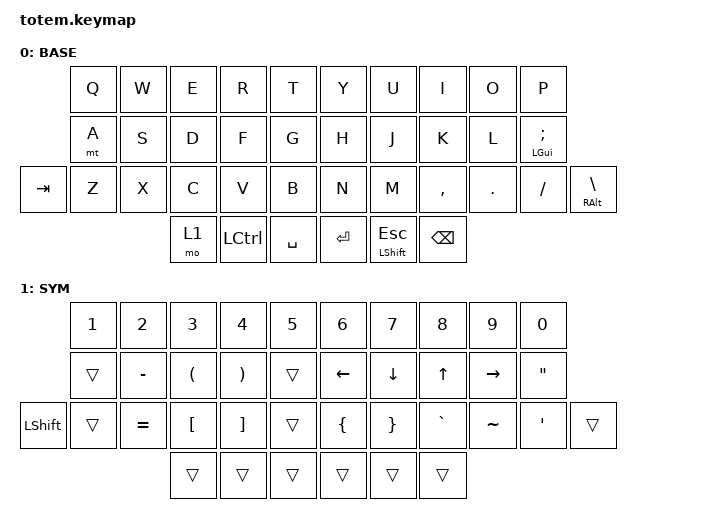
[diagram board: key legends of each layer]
//
//                                                        ▀▀▀▀▀     ▀▀▀▀▀          ▀▀█▀▀
//                                                        ▄▀▀▀▄  ▄  ▄▀▀▀▄  ▄  ▄▀▀▀▄  █  ▄▀▀▀▄
//                                                        █   █  █  █   █  █  █   █  █  █   █
//                                                         ▀▀▀   █   ▀▀▀   █   ▀▀▀   ▀   ▀▀▀
//                                                               █      ▄▄▄█▄▄▄    █   █  
//                                                               ▀      █  █  █     █▄█
//                                                             ▀▀▀▀▀    █  █  █      ▀
//                                                                      ▀  ▀  ▀
//
// ▄▄▄▄▄▄▄▄▄▄▄▄▄▄▄▄▄▄▄▄▄▄▄▄▄▄▄▄▄▄▄▄▄▄▄▄▄▄▄▄▄▄▄▄▄▄▄▄▄▄▄▄▄▄▄▄▄▄▄▄▄▄▄▄▄▄▄▄▄▄▄▄▄▄▄▄▄▄▄▄▄▄▄▄▄▄▄▄▄▄▄▄▄▄▄▄▄▄▄▄▄▄▄▄▄▄▄▄▄▄▄▄▄▄▄▄▄▄▄▄▄▄▄▄▄▄▄▄▄▄▄▄▄▄▄▄▄▄▄▄▄▄▄▄▄▄▄▄▄
       

#include <behaviors.dtsi>
#include <dt-bindings/zmk/keys.h>
#include <dt-bindings/zmk/bt.h>
#include <dt-bindings/zmk/outputs.h>

#define BASE 0
#define SYM  1
/* #define SYM  2 */
/* #define ADJ  3 */
/* #define TVP1 4 */
/* #define TVP2 5 */

&mt {
  quick-tap-ms = <100>;
  global-quick-tap;
  flavor = "tap-preferred";
  tapping-term-ms = <170>;
};

/ {
    /*  combos { */
    /* }; */
    /**/
    /* macros { */
    /* }; */

        keymap {
                compatible = "zmk,keymap";
// ▄▄▄▄▄▄▄▄▄▄▄▄▄▄▄▄▄▄▄▄▄▄▄▄▄▄▄▄▄▄▄▄▄▄▄▄▄▄▄▄▄▄▄▄▄▄▄▄▄▄▄▄▄▄▄▄▄▄▄▄▄▄▄▄▄▄▄▄▄▄▄▄▄▄▄▄▄▄▄▄▄▄▄▄▄▄▄▄▄▄▄▄▄▄▄▄▄▄▄▄▄▄▄▄▄▄▄▄▄▄▄▄▄▄▄▄▄▄▄▄▄▄▄▄▄▄▄▄▄▄▄▄▄▄▄▄▄▄▄▄▄▄▄▄▄▄▄▄▄

                base_layer {
// ┏━━━━━━━━━━━━━━━━━━━━━━━━━━━━━━━━━━━━━━━┓
label= "BASE"                              ;
// ┗━━━━━━━━━━━━━━━━━━━━━━━━━━━━━━━━━━━━━━━┛
//             ┏━━━━━━━━━━━┳━━━━━━━━━━━┳━━━━━━━━━━━┳━━━━━━━━━━━┳━━━━━━━━━━━┓   ┏━━━━━━━━━━━┳━━━━━━━━━━━┳━━━━━━━━━━━┳━━━━━━━━━━━┳━━━━━━━━━━━┓
//             ┃     Q     ┃     W     ┃     E     ┃     R     ┃     T     ┃   ┃     Y     ┃     U     ┃     I     ┃     O     ┃     P     ┃
//             ┣━━━━━━━━━━━╋━━━━━━━━━━━╋━━━━━━━━━━━╋━━━━━━━━━━━╋━━━━━━━━━━━┫   ┣━━━━━━━━━━━╋━━━━━━━━━━━╋━━━━━━━━━━━╋━━━━━━━━━━━╋━━━━━━━━━━━┫
//             ┃     A     ┃     S     ┃     D     ┃     F     ┃     G     ┃   ┃     H     ┃     J     ┃     K     ┃     L     ┃     ;     ┃
// ┏━━━━━━━━━━━╋━━━━━━━━━━━╋━━━━━━━━━━━╋━━━━━━━━━━━╋━━━━━━━━━━━╋━━━━━━━━━━━┫   ┣━━━━━━━━━━━╋━━━━━━━━━━━╋━━━━━━━━━━━╋━━━━━━━━━━━╋━━━━━━━━━━━╋━━━━━━━━━━━┓
// ┃    TAB    ┃     Z     ┃     X     ┃     C     ┃     V     ┃     B     ┃   ┃     N     ┃     M     ┃     ,     ┃     .     ┃     /     ┃     \     ┃
// ┗━━━━━━━━━━━┻━━━━━━━━━━━┻━━━━━━━━━━━╋━━━━━━━━━━━╋━━━━━━━━━━━╋━━━━━━━━━━━┫   ┣━━━━━━━━━━━╋━━━━━━━━━━━╋━━━━━━━━━━━╋━━━━━━━━━━━┻━━━━━━━━━━━┻━━━━━━━━━━━┛
//                                     ┃     1     ┃   LCTRL   ┃    SPC    ┃   ┃   ENTER   ┃    ESC    ┃   BSPC    ┃
//                                     ┗━━━━━━━━━━━┻━━━━━━━━━━━┻━━━━━━━━━━━┛   ┗━━━━━━━━━━━┻━━━━━━━━━━━┻━━━━━━━━━━━┛
 bindings = <
// ╷           ╷           ╷           ╷           ╷           ╷           ╷   ╷           ╷           ╷           ╷           ╷           ╷           ╷

                &kp Q       &kp W       &kp E       &kp R       &kp T           &kp Y       &kp U         &kp I       &kp O       &kp P
                &mt A       &kp S       &kp D       &kp F       &kp G           &kp H       &kp J         &kp K       &kp L       &mt LGUI SEMI
    &kp TAB     &kp Z       &kp X       &kp C       &kp V       &kp B           &kp N       &kp M         &kp COMMA   &kp DOT     &kp FSLH    &mt RALT BSLH
                                        &mo 1       &kp LCTRL   &kp SPACE       &kp RET     &mt LSHFT ESC &kp BSPC
                        >;
                };

// ▄▄▄▄▄▄▄▄▄▄▄▄▄▄▄▄▄▄▄▄▄▄▄▄▄▄▄▄▄▄▄▄▄▄▄▄▄▄▄▄▄▄▄▄▄▄▄▄▄▄▄▄▄▄▄▄▄▄▄▄▄▄▄▄▄▄▄▄▄▄▄▄▄▄▄▄▄▄▄▄▄▄▄▄▄▄▄▄▄▄▄▄▄▄▄▄▄▄▄▄▄▄▄▄▄▄▄▄▄▄▄▄▄▄▄▄▄▄▄▄▄▄▄▄▄▄▄▄▄▄▄▄▄▄▄▄▄▄▄▄▄▄▄▄▄▄▄▄▄


                symbol_layer {
// ┏━━━━━━━━━━━━━━━━━━━━━━━━━━━━━━━━━━━━━━━┓
label= "SYM"                               ;
// ┗━━━━━━━━━━━━━━━━━━━━━━━━━━━━━━━━━━━━━━━┛
//             ┏━━━━━━━━━━━┳━━━━━━━━━━━┳━━━━━━━━━━━┳━━━━━━━━━━━┳━━━━━━━━━━━┓   ┏━━━━━━━━━━━┳━━━━━━━━━━━┳━━━━━━━━━━━┳━━━━━━━━━━━┳━━━━━━━━━━━┓
//             ┃     1     ┃     2     ┃     3     ┃     4     ┃     5     ┃   ┃     6     ┃     7     ┃     8     ┃     9     ┃     0     ┃
//             ┣━━━━━━━━━━━╋━━━━━━━━━━━╋━━━━━━━━━━━╋━━━━━━━━━━━╋━━━━━━━━━━━┫   ┣━━━━━━━━━━━╋━━━━━━━━━━━╋━━━━━━━━━━━╋━━━━━━━━━━━╋━━━━━━━━━━━┫
//             ┃           ┃     -     ┃     (     ┃     )     ┃           ┃   ┃    LEFT   ┃    DOWN   ┃     UP    ┃    RIGHT  ┃     "     ┃
// ┏━━━━━━━━━━━╋━━━━━━━━━━━╋━━━━━━━━━━━╋━━━━━━━━━━━╋━━━━━━━━━━━╋━━━━━━━━━━━┫   ┣━━━━━━━━━━━╋━━━━━━━━━━━╋━━━━━━━━━━━╋━━━━━━━━━━━╋━━━━━━━━━━━╋━━━━━━━━━━━┓
// ┃   LSHFT   ┃           ┃     =     ┃     [     ┃     ]     ┃           ┃   ┃     {     ┃     }     ┃     `     ┃      ~    ┃     '     ┃           ┃
// ┗━━━━━━━━━━━┻━━━━━━━━━━━┻━━━━━━━━━━━╋━━━━━━━━━━━╋━━━━━━━━━━━╋━━━━━━━━━━━┫   ┣━━━━━━━━━━━╋━━━━━━━━━━━╋━━━━━━━━━━━╋━━━━━━━━━━━┻━━━━━━━━━━━┻━━━━━━━━━━━┛
//                                     ┃           ┃           ┃           ┃   ┃           ┃           ┃           ┃
//                                     ┗━━━━━━━━━━━┻━━━━━━━━━━━┻━━━━━━━━━━━┛   ┗━━━━━━━━━━━┻━━━━━━━━━━━┻━━━━━━━━━━━┛
 bindings = <
// ╷           ╷           ╷           ╷           ╷           ╷           ╷   ╷           ╷           ╷           ╷           ╷           ╷           ╷

                &kp N1      &kp N2      &kp N3      &kp N4      &kp N5          &kp N6      &kp N7      &kp N8      &kp N9      &kp N0
                &trans      &kp MINUS   &kp LPAR    &kp RPAR    &trans          &kp LEFT    &kp DOWN    &kp UP      &kp RIGHT   &kp DQT
    &kp LSHFT   &trans      &kp EQUAL   &kp LBKT    &kp RBKT    &trans          &kp LBRC    &kp RBRC    &kp GRAVE   &kp TILDE   &kp SQT     &trans      
                                        &trans      &trans      &trans          &trans      &trans      &trans      
                        >;
                };

// ▄▄▄▄▄▄▄▄▄▄▄▄▄▄▄▄▄▄▄▄▄▄▄▄▄▄▄▄▄▄▄▄▄▄▄▄▄▄▄▄▄▄▄▄▄▄▄▄▄▄▄▄▄▄▄▄▄▄▄▄▄▄▄▄▄▄▄▄▄▄▄▄▄▄▄▄▄▄▄▄▄▄▄▄▄▄▄▄▄▄▄▄▄▄▄▄▄▄▄▄▄▄▄▄▄▄▄▄▄▄▄▄▄▄▄▄▄▄▄▄▄▄▄▄▄▄▄▄▄▄▄▄▄▄▄▄▄▄▄▄▄▄▄▄▄▄▄▄▄


/*                 sim_layer { */
/* // ┏━━━━━━━━━━━━━━━━━━━━━━━━━━━━━━━━━━━━━━━┓ */
/* label= "SYM"                               ; */
/* // ┗━━━━━━━━━━━━━━━━━━━━━━━━━━━━━━━━━━━━━━━┛ */
/* //             ┏━━━━━━━━━━━┳━━━━━━━━━━━┳━━━━━━━━━━━┳━━━━━━━━━━━┳━━━━━━━━━━━┓   ┏━━━━━━━━━━━┳━━━━━━━━━━━┳━━━━━━━━━━━┳━━━━━━━━━━━┳━━━━━━━━━━━┓ */
/* //             ┃     !     ┃     @     ┃     #     ┃     $     ┃     %     ┃   ┃     ˆ     ┃     &     ┃     Ü     ┃     '     ┃     "     ┃ */
/* //             ┣━━━━━━━━━━━╋━━━━━━━━━━━╋━━━━━━━━━━━╋━━━━━━━━━━━╋━━━━━━━━━━━┫   ┣━━━━━━━━━━━╋━━━━━━━━━━━╋━━━━━━━━━━━╋━━━━━━━━━━━╋━━━━━━━━━━━┫ */
/* //             ┃     Ä     ┃           ┃    SZ     ┃           ┃           ┃   ┃   MUTE    ┃   YEN     ┃   EURO    ┃  POUND    ┃     Ö     ┃ */
/* // ┏━━━━━━━━━━━╋━━━━━━━━━━━╋━━━━━━━━━━━╋━━━━━━━━━━━╋━━━━━━━━━━━╋━━━━━━━━━━━┫   ┣━━━━━━━━━━━╋━━━━━━━━━━━╋━━━━━━━━━━━╋━━━━━━━━━━━╋━━━━━━━━━━━╋━━━━━━━━━━━┓ */
/* // ┃           ┃  EMAIL1   ┃  EMAIL2   ┃           ┃           ┃           ┃   ┃   VOL-    ┃   VOL+    ┃   LAST    ┃   NEXT    ┃     \     ┃           ┃ */
/* // ┗━━━━━━━━━━━┻━━━━━━━━━━━┻━━━━━━━━━━━╋━━━━━━━━━━━╋━━━━━━━━━━━╋━━━━━━━━━━━┫   ┣━━━━━━━━━━━╋━━━━━━━━━━━╋━━━━━━━━━━━╋━━━━━━━━━━━┻━━━━━━━━━━━┻━━━━━━━━━━━┛ */
/* //                                     ┃           ┃    GIF    ┃    ADJ    ┃   ┃           ┃           ┃           ┃ */
/* //                                     ┗━━━━━━━━━━━┻━━━━━━━━━━━┻━━━━━━━━━━━┛   ┗━━━━━━━━━━━┻━━━━━━━━━━━┻━━━━━━━━━━━┛ */
/*  bindings = < */
/* // ╷           ╷           ╷           ╷           ╷           ╷           ╷   ╷           ╷           ╷           ╷           ╷           ╷           ╷ */
/**/
/*                 &kp EXCL    &kp AT      &kp HASH    &kp DLLR    &kp PRCNT       &kp CARET   &kp AMPS    &kp RA(U)   &kp SQT     &kp DQT        */
/*                 &kp RA(A)   &trans      &kp RA(S)   &trans      &trans          &kp C_MUTE  &kp LS(RA(N4)) &kp RA(N5) &kp RA(N4)   &kp RA(O)  */
/*     &trans      &kp RA(F18) &kp RA(F19) &trans      &trans      &trans          &kp C_VOL_DN &kp C_VOL_UP &kp C_PREV &kp C_NEXT  &kp BSLH   &trans          */
/*                                         &trans      &gif        &mo ADJ         &trans      &kp C_PP    &trans       */
/*                         >; */
/*                 }; */
/**/
// ▄▄▄▄▄▄▄▄▄▄▄▄▄▄▄▄▄▄▄▄▄▄▄▄▄▄▄▄▄▄▄▄▄▄▄▄▄▄▄▄▄▄▄▄▄▄▄▄▄▄▄▄▄▄▄▄▄▄▄▄▄▄▄▄▄▄▄▄▄▄▄▄▄▄▄▄▄▄▄▄▄▄▄▄▄▄▄▄▄▄▄▄▄▄▄▄▄▄▄▄▄▄▄▄▄▄▄▄▄▄▄▄▄▄▄▄▄▄▄▄▄▄▄▄▄▄▄▄▄▄▄▄▄▄▄▄▄▄▄▄▄▄▄▄▄▄▄▄▄


/*                 adjust_layer { */
/* // ┏━━━━━━━━━━━━━━━━━━━━━━━━━━━━━━━━━━━━━━━┓ */
/* label= "ADJ"                               ; */
/* // ┗━━━━━━━━━━━━━━━━━━━━━━━━━━━━━━━━━━━━━━━┛ */
/* //             ┏━━━━━━━━━━━┳━━━━━━━━━━━┳━━━━━━━━━━━┳━━━━━━━━━━━┳━━━━━━━━━━━┓   ┏━━━━━━━━━━━┳━━━━━━━━━━━┳━━━━━━━━━━━┳━━━━━━━━━━━┳━━━━━━━━━━━┓ */
/* //             ┃   RESET   ┃ BT CLEAR  ┃  OUT TOG  ┃           ┃           ┃   ┃           ┃    F7     ┃    F8     ┃    F9     ┃    F12    ┃ */
/* //             ┣━━━━━━━━━━━╋━━━━━━━━━━━╋━━━━━━━━━━━╋━━━━━━━━━━━╋━━━━━━━━━━━┫   ┣━━━━━━━━━━━╋━━━━━━━━━━━╋━━━━━━━━━━━╋━━━━━━━━━━━╋━━━━━━━━━━━┫ */
/* //             ┃ BOOTLOAD  ┃ BT NEXT   ┃           ┃           ┃           ┃   ┃           ┃    F4     ┃    F5     ┃    F6     ┃    F11    ┃ */
/* // ┏━━━━━━━━━━━╋━━━━━━━━━━━╋━━━━━━━━━━━╋━━━━━━━━━━━╋━━━━━━━━━━━╋━━━━━━━━━━━┫   ┣━━━━━━━━━━━╋━━━━━━━━━━━╋━━━━━━━━━━━╋━━━━━━━━━━━╋━━━━━━━━━━━╋━━━━━━━━━━━┓ */
/* // ┃           ┃           ┃ BT PREV   ┃           ┃           ┃           ┃   ┃           ┃    F1     ┃    F2     ┃    F3     ┃    F10    ┃           ┃ */
/* // ┗━━━━━━━━━━━┻━━━━━━━━━━━┻━━━━━━━━━━━╋━━━━━━━━━━━╋━━━━━━━━━━━╋━━━━━━━━━━━┫   ┣━━━━━━━━━━━╋━━━━━━━━━━━╋━━━━━━━━━━━╋━━━━━━━━━━━┻━━━━━━━━━━━┻━━━━━━━━━━━┛ */
/* //                                     ┃           ┃           ┃           ┃   ┃           ┃           ┃           ┃ */
/* //                                     ┗━━━━━━━━━━━┻━━━━━━━━━━━┻━━━━━━━━━━━┛   ┗━━━━━━━━━━━┻━━━━━━━━━━━┻━━━━━━━━━━━┛ */
/*  bindings = < */
/* // ╷           ╷           ╷           ╷           ╷           ╷           ╷   ╷           ╷           ╷           ╷           ╷           ╷           ╷ */
/**/
/*                 &sys_reset  &bt BT_CLR &out OUT_TOG &trans      &trans          &trans      &kp F7      &kp F8      &kp F9      &kp F12 */
/*                 &bootloader &bt BT_NXT  &trans      &trans      &trans          &trans      &kp F4      &kp F5      &kp F6      &kp F11   */
/*     &trans      &trans      &bt BT_PRV  &trans      &trans      &trans          &trans      &kp F1      &kp F2      &kp F3      &kp F10     &trans          */
/*                                         &trans      &trans      &trans          &trans      &trans      &trans       */
/*                         >; */
/*                 }; */
/**/
// ▄▄▄▄▄▄▄▄▄▄▄▄▄▄▄▄▄▄▄▄▄▄▄▄▄▄▄▄▄▄▄▄▄▄▄▄▄▄▄▄▄▄▄▄▄▄▄▄▄▄▄▄▄▄▄▄▄▄▄▄▄▄▄▄▄▄▄▄▄▄▄▄▄▄▄▄▄▄▄▄▄▄▄▄▄▄▄▄▄▄▄▄▄▄▄▄▄▄▄▄▄▄▄▄▄▄▄▄▄▄▄▄▄▄▄▄▄▄▄▄▄▄▄▄▄▄▄▄▄▄▄▄▄▄▄▄▄▄▄▄▄▄▄▄▄▄▄▄▄
/**/
/**/
/*                 tvp1_layer { */
/* // ┏━━━━━━━━━━━━━━━━━━━━━━━━━━━━━━━━━━━━━━━┓ */
/* label= "TVP 1"                             ; */
/* // ┗━━━━━━━━━━━━━━━━━━━━━━━━━━━━━━━━━━━━━━━┛ */
/* //             ┏━━━━━━━━━━━┳━━━━━━━━━━━┳━━━━━━━━━━━┳━━━━━━━━━━━┳━━━━━━━━━━━┓   ┏━━━━━━━━━━━┳━━━━━━━━━━━┳━━━━━━━━━━━┳━━━━━━━━━━━┳━━━━━━━━━━━┓ */
/* //             ┃ NEXT FILE ┃ MARK IN   ┃ ROTATE    ┃ MARK OUT  ┃ SHOW SNAP ┃   ┃           ┃           ┃           ┃           ┃           ┃ */
/* //             ┣━━━━━━━━━━━╋━━━━━━━━━━━╋━━━━━━━━━━━╋━━━━━━━━━━━╋━━━━━━━━━━━┫   ┣━━━━━━━━━━━╋━━━━━━━━━━━╋━━━━━━━━━━━╋━━━━━━━━━━━╋━━━━━━━━━━━┫ */
/* //             ┃ TVP II    ┃ LEFT      ┃ PAN       ┃ RIGHT     ┃ PLAY/FLIP ┃   ┃           ┃           ┃           ┃           ┃           ┃ */
/* // ┏━━━━━━━━━━━╋━━━━━━━━━━━╋━━━━━━━━━━━╋━━━━━━━━━━━╋━━━━━━━━━━━╋━━━━━━━━━━━┫   ┣━━━━━━━━━━━╋━━━━━━━━━━━╋━━━━━━━━━━━╋━━━━━━━━━━━╋━━━━━━━━━━━╋━━━━━━━━━━━┓ */
/* // ┃ FULLSCR   ┃ SHIFT     ┃ COPY      ┃ DELETE    ┃ PASTE     ┃ IMG MARK  ┃   ┃           ┃           ┃           ┃           ┃           ┃           ┃ */
/* // ┗━━━━━━━━━━━┻━━━━━━━━━━━┻━━━━━━━━━━━╋━━━━━━━━━━━╋━━━━━━━━━━━╋━━━━━━━━━━━┫   ┣━━━━━━━━━━━╋━━━━━━━━━━━╋━━━━━━━━━━━╋━━━━━━━━━━━┻━━━━━━━━━━━┻━━━━━━━━━━━┛ */
/* //                                     ┃           ┃ UNDO/SAVE ┃  SEL/MOV  ┃   ┃           ┃           ┃           ┃ */
/* //                                     ┗━━━━━━━━━━━┻━━━━━━━━━━━┻━━━━━━━━━━━┛   ┗━━━━━━━━━━━┻━━━━━━━━━━━┻━━━━━━━━━━━┛ */
/*  bindings = < */
/* // ╷           ╷           ╷           ╷           ╷           ╷           ╷   ╷           ╷           ╷           ╷           ╷           ╷           ╷ */
/**/
/*                 &kp TAB     &kp I       &kp LC(LALT) &kp O      &kp LC(F20)     &none       &none       &none       &none       &none */
/*                 &lt TVP2 L  &kp LEFT    &kp LALT    &kp RIGHT   &kp SPACE       &none       &none       &none       &none       &none */
/*     &kp J       &kp LSHFT   &kp LC(C)   &kp BSPC    &kp LC(V)   &kp LC(F19)     &none       &none       &none       &none       &none       &none         */
/*                                         &trans      &kp LC(F14) &kp LC(F13)     &none       &none       &none     */
/*                         >; */
/*                 }; */
/**/
// ▄▄▄▄▄▄▄▄▄▄▄▄▄▄▄▄▄▄▄▄▄▄▄▄▄▄▄▄▄▄▄▄▄▄▄▄▄▄▄▄▄▄▄▄▄▄▄▄▄▄▄▄▄▄▄▄▄▄▄▄▄▄▄▄▄▄▄▄▄▄▄▄▄▄▄▄▄▄▄▄▄▄▄▄▄▄▄▄▄▄▄▄▄▄▄▄▄▄▄▄▄▄▄▄▄▄▄▄▄▄▄▄▄▄▄▄▄▄▄▄▄▄▄▄▄▄▄▄▄▄▄▄▄▄▄▄▄▄▄▄▄▄▄▄▄▄▄▄▄
/**/
/**/
/*                 tvp2_layer { */
/* // ┏━━━━━━━━━━━━━━━━━━━━━━━━━━━━━━━━━━━━━━━┓ */
/* label= "TVP 2"                             ; */
/* // ┗━━━━━━━━━━━━━━━━━━━━━━━━━━━━━━━━━━━━━━━┛ */
/* //             ┏━━━━━━━━━━━┳━━━━━━━━━━━┳━━━━━━━━━━━┳━━━━━━━━━━━┳━━━━━━━━━━━┓   ┏━━━━━━━━━━━┳━━━━━━━━━━━┳━━━━━━━━━━━┳━━━━━━━━━━━┳━━━━━━━━━━━┓ */
/* //             ┃ SOLO      ┃ TOGGLE IN ┃ RESET ROT ┃ TOGGLE OUT┃ TAKE SNAP ┃   ┃           ┃           ┃           ┃           ┃           ┃ */
/* //             ┣━━━━━━━━━━━╋━━━━━━━━━━━╋━━━━━━━━━━━╋━━━━━━━━━━━╋━━━━━━━━━━━┫   ┣━━━━━━━━━━━╋━━━━━━━━━━━╋━━━━━━━━━━━╋━━━━━━━━━━━╋━━━━━━━━━━━┫ */
/* //             ┃ ---       ┃ LAST KEY  ┃ NEW KEY   ┃ NEXT KEY  ┃ ENTER     ┃   ┃           ┃           ┃           ┃           ┃           ┃ */
/* // ┏━━━━━━━━━━━╋━━━━━━━━━━━╋━━━━━━━━━━━╋━━━━━━━━━━━╋━━━━━━━━━━━╋━━━━━━━━━━━┫   ┣━━━━━━━━━━━╋━━━━━━━━━━━╋━━━━━━━━━━━╋━━━━━━━━━━━╋━━━━━━━━━━━╋━━━━━━━━━━━┓ */
/* // ┃           ┃ FULLSCR   ┃ CPY2BRUSH ┃ DEL HEAD  ┃ PSTinPLACE┃ BOOK MARK ┃   ┃           ┃           ┃           ┃           ┃           ┃           ┃ */
/* // ┗━━━━━━━━━━━┻━━━━━━━━━━━┻━━━━━━━━━━━╋━━━━━━━━━━━╋━━━━━━━━━━━╋━━━━━━━━━━━┫   ┣━━━━━━━━━━━╋━━━━━━━━━━━╋━━━━━━━━━━━╋━━━━━━━━━━━┻━━━━━━━━━━━┻━━━━━━━━━━━┛ */
/* //                                     ┃           ┃ REDO/SAV1 ┃TRANS/WARP ┃   ┃           ┃           ┃           ┃ */
/* //                                     ┗━━━━━━━━━━━┻━━━━━━━━━━━┻━━━━━━━━━━━┛   ┗━━━━━━━━━━━┻━━━━━━━━━━━┻━━━━━━━━━━━┛ */
/*  bindings = < */
/* // ╷           ╷           ╷           ╷           ╷           ╷           ╷   ╷           ╷           ╷           ╷           ╷           ╷           ╷ */
/**/
/*                 &kp LC(F18) &kp LS(I)  &kp LS(HOME) &kp LS(O)   &kp LS(F)       &trans      &kp F7      &kp F8      &kp F9      &kp F12 */
/*                 &trans      &kp LS(LEFT) &kp LC(F17) &kp LS(RIGHT) &kp RET      &trans      &kp F4      &kp F5      &kp F6      &kp F11   */
/*     &trans      &kp J       &kp LS(C)   &kp LC(F16) &kp LS(V)   &kp LC(F15)     &trans      &kp F1      &kp F2      &kp F3      &kp F10     &trans          */
/*                                         &trans      &kp LC(F12) &kp LC(F11)     &trans      &trans      &trans       */
/*                         >; */
/*                 }; */
        };
};
